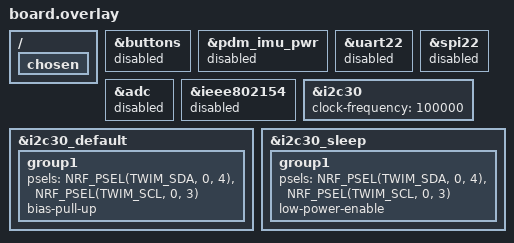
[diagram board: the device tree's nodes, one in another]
/* Keep only radio and temporary IMU shutdown bus active. */
&buttons { status = "disabled"; };
&pdm_imu_pwr { status = "disabled"; };
/delete-node/ &imu_power_default_on;
&uart22 { status = "disabled"; };
&spi22 { status = "disabled"; };
&adc { status = "disabled"; };
&ieee802154 { status = "disabled"; };
/ { chosen { /delete-property/ zephyr,ieee802154; }; };
/* IMU is permanently powered on this carrier. Briefly use I2C to shut it
 * down, including after a warm reset that left motion wake enabled. */
&i2c30 { status = "okay"; clock-frequency = <100000>; };
&i2c30_default {
 group1 {
  psels = <NRF_PSEL(TWIM_SDA, 0, 4)>, <NRF_PSEL(TWIM_SCL, 0, 3)>;
  bias-pull-up;
 };
};
&i2c30_sleep {
 group1 {
  psels = <NRF_PSEL(TWIM_SDA, 0, 4)>, <NRF_PSEL(TWIM_SCL, 0, 3)>;
  low-power-enable;
 };
};
